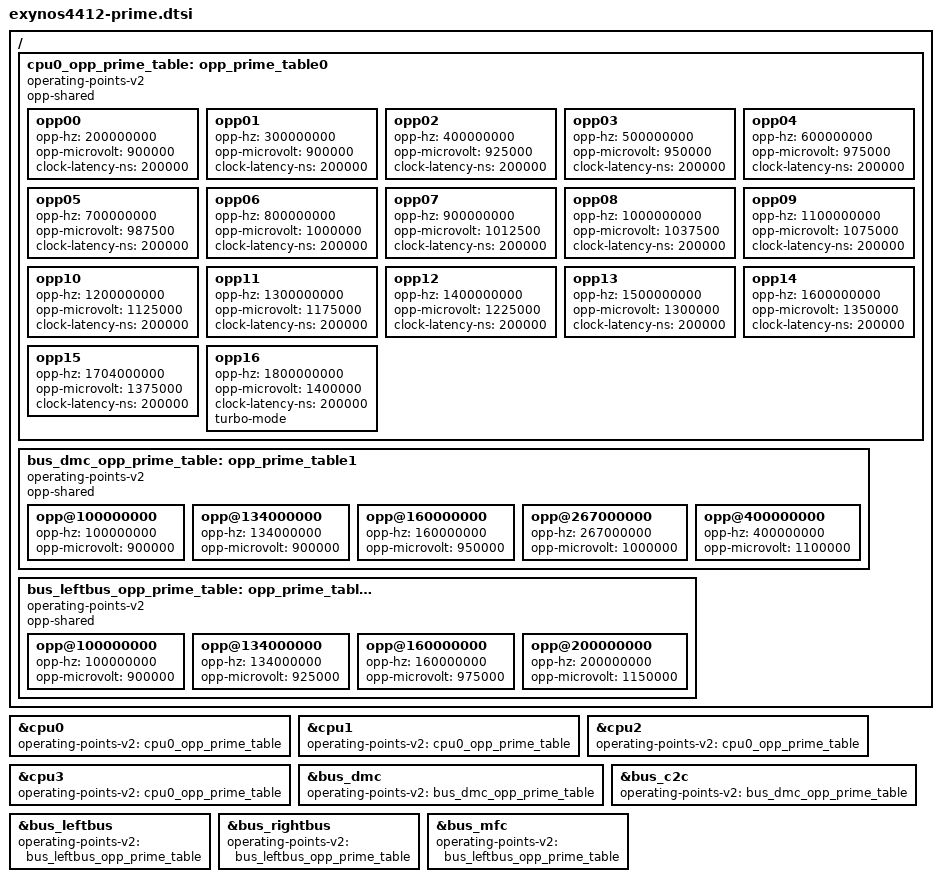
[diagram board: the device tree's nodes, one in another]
/*
 * Samsung's Exynos4412 SoC Prime device tree source
 *
 * This program is free software; you can redistribute it and/or modify
 * it under the terms of the GNU General Public License version 2 as
 * published by the Free Software Foundation.
*/

/ {
	cpu0_opp_prime_table: opp_prime_table0 {
		compatible = "operating-points-v2";
		opp-shared;

		opp00 {
			opp-hz = /bits/ 64 <200000000>;
			opp-microvolt = <900000>;
			clock-latency-ns = <200000>;
		};
		opp01 {
			opp-hz = /bits/ 64 <300000000>;
			opp-microvolt = <900000>;
			clock-latency-ns = <200000>;
		};
		opp02 {
			opp-hz = /bits/ 64 <400000000>;
			opp-microvolt = <925000>;
			clock-latency-ns = <200000>;
		};
		opp03 {
			opp-hz = /bits/ 64 <500000000>;
			opp-microvolt = <950000>;
			clock-latency-ns = <200000>;
		};
		opp04 {
			opp-hz = /bits/ 64 <600000000>;
			opp-microvolt = <975000>;
			clock-latency-ns = <200000>;
		};
		opp05 {
			opp-hz = /bits/ 64 <700000000>;
			opp-microvolt = <987500>;
			clock-latency-ns = <200000>;
		};
		opp06 {
			opp-hz = /bits/ 64 <800000000>;
			opp-microvolt = <1000000>;
			clock-latency-ns = <200000>;
		};
		opp07 {
			opp-hz = /bits/ 64 <900000000>;
			opp-microvolt = <1012500>;
			clock-latency-ns = <200000>;
		};
		opp08 {
			opp-hz = /bits/ 64 <1000000000>;
			opp-microvolt = <1037500>;
			clock-latency-ns = <200000>;
		};
		opp09 {
			opp-hz = /bits/ 64 <1100000000>;
			opp-microvolt = <1075000>;
			clock-latency-ns = <200000>;
		};
		opp10 {
			opp-hz = /bits/ 64 <1200000000>;
			opp-microvolt = <1125000>;
			clock-latency-ns = <200000>;
		};
		opp11 {
			opp-hz = /bits/ 64 <1300000000>;
			opp-microvolt = <1175000>;
			clock-latency-ns = <200000>;
		};
		opp12 {
			opp-hz = /bits/ 64 <1400000000>;
			opp-microvolt = <1225000>;
			clock-latency-ns = <200000>;
		};
		opp13 {
			opp-hz = /bits/ 64 <1500000000>;
			opp-microvolt = <1300000>;
			clock-latency-ns = <200000>;
		};
		opp14 {
			opp-hz = /bits/ 64 <1600000000>;
			opp-microvolt = <1350000>;
			clock-latency-ns = <200000>;
		};
		opp15 {
			opp-hz = /bits/ 64 <1704000000>;
			opp-microvolt = <1375000>;
			clock-latency-ns = <200000>;
		};
		opp16 {
			opp-hz = /bits/ 64 <1800000000>;
			opp-microvolt = <1400000>;
			clock-latency-ns = <200000>;
			turbo-mode;
		};
	};

	bus_dmc_opp_prime_table: opp_prime_table1 {
		compatible = "operating-points-v2";
		opp-shared;

		opp@100000000 {
			opp-hz = /bits/ 64 <100000000>;
			opp-microvolt = <900000>;
		};
		opp@134000000 {
			opp-hz = /bits/ 64 <134000000>;
			opp-microvolt = <900000>;
		};
		opp@160000000 {
			opp-hz = /bits/ 64 <160000000>;
			opp-microvolt = <950000>;
		};
		opp@267000000 {
			opp-hz = /bits/ 64 <267000000>;
			opp-microvolt = <1000000>;
		};
		opp@400000000 {
			opp-hz = /bits/ 64 <400000000>;
			opp-microvolt = <1100000>;
		};
	};

	bus_leftbus_opp_prime_table: opp_prime_table2 {
		compatible = "operating-points-v2";
		opp-shared;

		opp@100000000 {
			opp-hz = /bits/ 64 <100000000>;
			opp-microvolt = <900000>;
		};
		opp@134000000 {
			opp-hz = /bits/ 64 <134000000>;
			opp-microvolt = <925000>;
		};
		opp@160000000 {
			opp-hz = /bits/ 64 <160000000>;
			opp-microvolt = <975000>;
		};
		opp@200000000 {
			opp-hz = /bits/ 64 <200000000>;
			opp-microvolt = <1150000>;
		};
	};
};

&cpu0 {
	operating-points-v2 = <&cpu0_opp_prime_table>;
};

&cpu1 {
	operating-points-v2 = <&cpu0_opp_prime_table>;
};

&cpu2 {
	operating-points-v2 = <&cpu0_opp_prime_table>;
};

&cpu3 {
	operating-points-v2 = <&cpu0_opp_prime_table>;
};

&bus_dmc {
	operating-points-v2 = <&bus_dmc_opp_prime_table>;
};

&bus_c2c {
	operating-points-v2 = <&bus_dmc_opp_prime_table>;
};

&bus_leftbus {
	operating-points-v2 = <&bus_leftbus_opp_prime_table>;
};

&bus_rightbus {
	operating-points-v2 = <&bus_leftbus_opp_prime_table>;
};

&bus_mfc {
	operating-points-v2 = <&bus_leftbus_opp_prime_table>;
};
